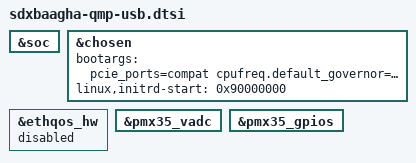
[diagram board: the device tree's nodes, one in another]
// SPDX-License-Identifier: BSD-3-Clause
/*
 * Copyright (c) Qualcomm Technologies, Inc. and/or its subsidiaries.
 */

&soc {
};

&chosen {
	bootargs = "pcie_ports=compat cpufreq.default_governor=performance reboot=w";
	linux,initrd-start = <0x90000000>;
};

&ethqos_hw {
	status = "disabled";
};

&pmx35_vadc {
	/delete-property/ pinctrl-0;
	/delete-property/ pinctrl-names;
	/delete-node/ pmx35_batt_id;
};

&pmx35_gpios {
	/delete-node/ batt_id;
};
